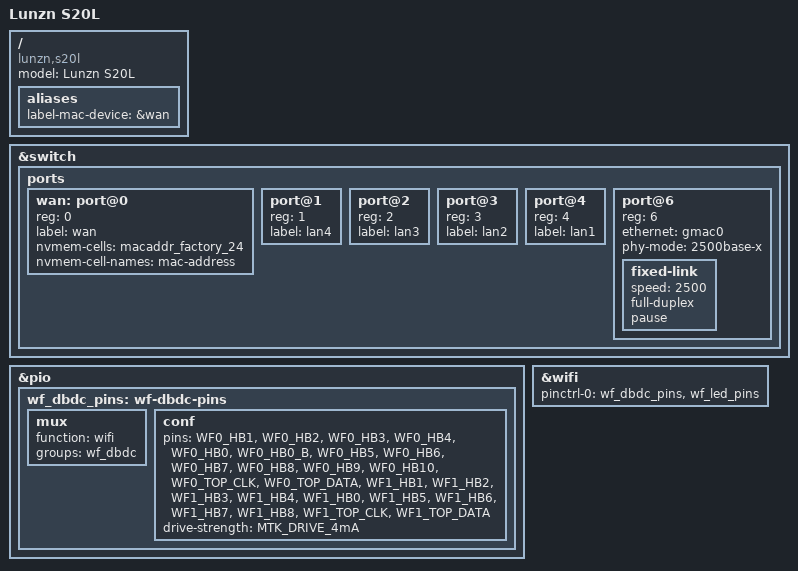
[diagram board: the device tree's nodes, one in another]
// SPDX-License-Identifier: GPL-2.0-or-later OR MIT

/dts-v1/;
#include "mt7986a-lunzn-s20.dtsi"

/ {
	model = "Lunzn S20L";
	compatible = "lunzn,s20l", "mediatek,mt7986a";

	aliases {
		label-mac-device = &wan;
	};
};

&switch {
	ports {
		#address-cells = <1>;
		#size-cells = <0>;

		wan: port@0 {
			reg = <0>;
			label = "wan";

			nvmem-cells = <&macaddr_factory_24>;
			nvmem-cell-names = "mac-address";
		};

		port@1 {
			reg = <1>;
			label = "lan4";
		};

		port@2 {
			reg = <2>;
			label = "lan3";
		};

		port@3 {
			reg = <3>;
			label = "lan2";
		};

		port@4 {
			reg = <4>;
			label = "lan1";
		};

		port@6 {
			reg = <6>;
			ethernet = <&gmac0>;
			phy-mode = "2500base-x";

			fixed-link {
				speed = <2500>;
				full-duplex;
				pause;
			};
		};
	};
};

&pio {
	wf_dbdc_pins: wf-dbdc-pins {
		mux {
			function = "wifi";
			groups = "wf_dbdc";
		};
		conf {
			pins = "WF0_HB1", "WF0_HB2", "WF0_HB3", "WF0_HB4",
			       "WF0_HB0", "WF0_HB0_B", "WF0_HB5", "WF0_HB6",
			       "WF0_HB7", "WF0_HB8", "WF0_HB9", "WF0_HB10",
			       "WF0_TOP_CLK", "WF0_TOP_DATA", "WF1_HB1",
			       "WF1_HB2", "WF1_HB3", "WF1_HB4", "WF1_HB0",
			       "WF1_HB5", "WF1_HB6", "WF1_HB7", "WF1_HB8",
			       "WF1_TOP_CLK", "WF1_TOP_DATA";
			drive-strength = <MTK_DRIVE_4mA>;
		};
	};
};

&wifi {
	pinctrl-names = "dbdc";
	pinctrl-0 = <&wf_dbdc_pins>, <&wf_led_pins>;
};
